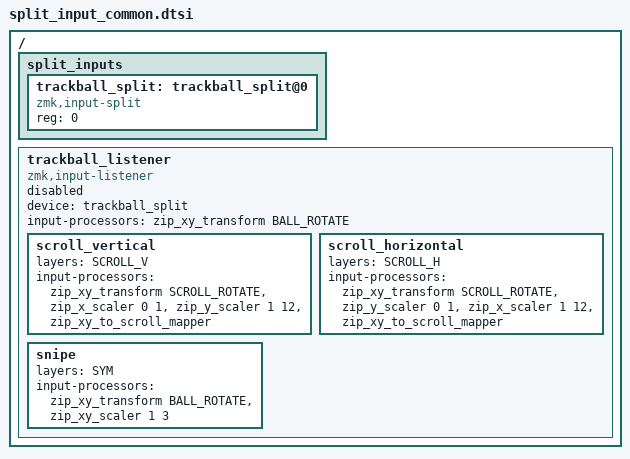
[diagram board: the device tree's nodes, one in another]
#include <dt-bindings/zmk/input_transform.h>
#include <input/processors.dtsi>

#define DEF 0
#define MOUSE 1
#define SYM 2
#define NUM 3
#define FN 4
#define GENSHIN 5
#define SCROLL_V 7
#define SCROLL_H 8

// Поворот сенсора: так курсор движется правильно при установленном шаре.
#define BALL_ROTATE (INPUT_TRANSFORM_XY_SWAP | INPUT_TRANSFORM_X_INVERT | INPUT_TRANSFORM_Y_INVERT)
// Для скролла ось Y инвертирована относительно курсора: шар вверх = прокрутка вверх (как колесо мыши).
// Если направление не нравится, поменяй X_INVERT / добавь Y_INVERT здесь.
#define SCROLL_ROTATE (INPUT_TRANSFORM_XY_SWAP | INPUT_TRANSFORM_X_INVERT)

/ {
    split_inputs {
        #address-cells = <1>;
        #size-cells = <0>;

        trackball_split: trackball_split@0 {
            compatible = "zmk,input-split";
            reg = <0>;
        };
    };

    // Включается только на донгле (central), см. charybdis_dongle.overlay.
    trackball_listener: trackball_listener {
        compatible = "zmk,input-listener";
        status = "disabled";
        device = <&trackball_split>;

        // Обычное движение курсора: применяется, когда ни один слой ниже не активен.
        input-processors = <&zip_xy_transform BALL_ROTATE>;

        // Слои-переопределения проверяются ПО ПОРЯДКУ, срабатывает первый подходящий.
        // Поэтому базовый слой 0 здесь указывать нельзя: он активен всегда и перекроет всё остальное.

        // SCROLL_V (&mo 7, на слое Symbol клавиша V): только вертикальный скролл.
        scroll_vertical {
            layers = <SCROLL_V>;
            input-processors = <
                &zip_xy_transform SCROLL_ROTATE
                &zip_x_scaler 0 1
                &zip_y_scaler 1 12
                &zip_xy_to_scroll_mapper
            >;
        };

        // SCROLL_H (&mo 8, на слое Symbol клавиша B): только горизонтальный скролл.
        scroll_horizontal {
            layers = <SCROLL_H>;
            input-processors = <
                &zip_xy_transform SCROLL_ROTATE
                &zip_y_scaler 0 1
                &zip_x_scaler 1 12
                &zip_xy_to_scroll_mapper
            >;
        };

        // SYMBOL: точный (медленный) курсор.
        snipe {
            layers = <SYM>;
            input-processors = <
                &zip_xy_transform BALL_ROTATE
                &zip_xy_scaler 1 3
            >;
        };
    };
};
